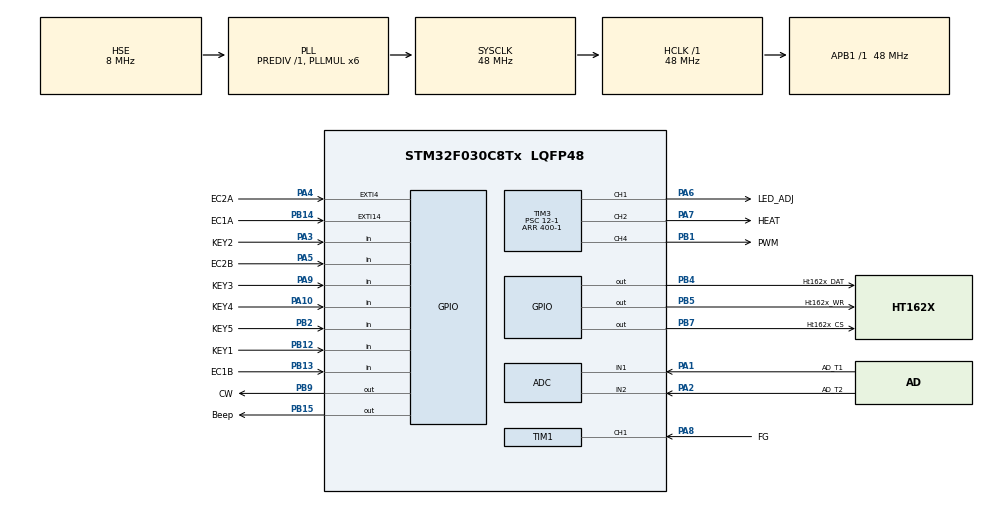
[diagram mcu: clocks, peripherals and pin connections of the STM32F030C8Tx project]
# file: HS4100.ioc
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ADC.DMAContinuousRequests=ENABLE
ADC.ExternalTrigConv=ADC_EXTERNALTRIGCONV_T15_TRGO
ADC.SamplingTime=ADC_SAMPLETIME_239CYCLES_5
Dma.ADC.0.Direction=DMA_PERIPH_TO_MEMORY
Dma.ADC.0.Instance=DMA1_Channel1
Dma.ADC.0.MemDataAlignment=DMA_MDATAALIGN_HALFWORD
Dma.ADC.0.MemInc=DMA_MINC_ENABLE
Dma.ADC.0.Mode=DMA_CIRCULAR
Dma.ADC.0.PeriphDataAlignment=DMA_PDATAALIGN_HALFWORD
Dma.ADC.0.PeriphInc=DMA_PINC_DISABLE
Dma.ADC.0.Priority=DMA_PRIORITY_HIGH
Dma.Request0=ADC
Mcu.Family=STM32F0
Mcu.Name=STM32F030C8Tx
Mcu.Package=LQFP48
NVIC.ADC1_IRQn=true\:0\:0\:false\:false\:true\:true\:true\:true
NVIC.DMA1_Channel1_IRQn=true\:0\:0\:false\:false\:true\:false\:true\:true
NVIC.EXTI4_15_IRQn=true\:1\:0\:true\:false\:true\:true\:true\:true
NVIC.TIM14_IRQn=true\:2\:0\:true\:false\:true\:true\:true\:true
NVIC.TIM15_IRQn=true\:0\:0\:false\:false\:true\:true\:true\:true
NVIC.TIM1_CC_IRQn=true\:0\:0\:false\:false\:true\:true\:true\:true
NVIC.TIM6_IRQn=true\:2\:0\:true\:false\:true\:true\:true\:true
PA1.GPIO_Label=AD_T1
PA1.Mode=IN1
PA1.Signal=ADC_IN1
PA10.GPIO_Label=KEY4
PA10.Signal=GPIO_Input
PA13.Mode=Serial_Wire
PA13.Signal=SYS_SWDIO
PA14.Mode=Serial_Wire
PA14.Signal=SYS_SWCLK
PA2.GPIO_Label=AD_T2
PA2.Mode=IN2
PA2.Signal=ADC_IN2
PA3.GPIO_Label=KEY2
PA3.Signal=GPIO_Input
PA4.GPIO_Label=EC2A
PA4.Signal=GPXTI4
PA5.GPIO_Label=EC2B
PA5.Signal=GPIO_Input
PA6.GPIO_Label=LED_ADJ
PA6.Signal=S_TIM3_CH1
PA7.GPIO_Label=HEAT
PA7.Signal=S_TIM3_CH2
PA8.GPIO_Label=FG
PA8.Signal=S_TIM1_CH1
PA9.GPIO_Label=KEY3
PA9.Signal=GPIO_Input
PB1.GPIO_Label=PWM
PB1.Signal=S_TIM3_CH4
PB12.GPIO_Label=KEY1
PB12.Signal=GPIO_Input
PB13.GPIO_Label=EC1B
PB13.Signal=GPIO_Input
PB14.GPIO_Label=EC1A
PB14.Signal=GPXTI14
PB15.GPIO_Label=Beep
PB15.Signal=GPIO_Output
PB2.GPIO_Label=KEY5
PB2.Signal=GPIO_Input
PB4.GPIO_Label=Ht162x_DAT
PB4.GPIO_ModeDefaultOutputPP=GPIO_MODE_OUTPUT_PP
PB4.GPIO_PuPd=GPIO_PULLUP
PB4.GPIO_Speed=GPIO_SPEED_FREQ_HIGH
PB4.PinState=GPIO_PIN_SET
PB4.Signal=GPIO_Output
PB5.GPIO_Label=Ht162x_WR
PB5.GPIO_PuPd=GPIO_PULLUP
PB5.GPIO_Speed=GPIO_SPEED_FREQ_HIGH
PB5.PinState=GPIO_PIN_SET
PB5.Signal=GPIO_Output
PB7.GPIO_Label=Ht162x_CS
PB7.GPIO_PuPd=GPIO_PULLUP
PB7.GPIO_Speed=GPIO_SPEED_FREQ_HIGH
PB7.PinState=GPIO_PIN_SET
PB7.Signal=GPIO_Output
PB9.GPIO_Label=CW
PB9.Signal=GPIO_Output
PF0-OSC_IN.Mode=HSE-External-Oscillator
PF0-OSC_IN.Signal=RCC_OSC_IN
PF1-OSC_OUT.Mode=HSE-External-Oscillator
PF1-OSC_OUT.Signal=RCC_OSC_OUT
ProjectManager.HeapSize=0x200
ProjectManager.StackSize=0x400
ProjectManager.TargetToolchain=MDK-ARM V5.32
RCC.AHBFreq_Value=48000000
RCC.APB1Freq_Value=48000000
RCC.APB1TimFreq_Value=48000000
RCC.HCLKFreq_Value=48000000
RCC.PLLMUL=RCC_PLL_MUL6
RCC.PLLSourceVirtual=RCC_PLLSOURCE_HSE
RCC.SYSCLKFreq_VALUE=48000000
RCC.SYSCLKSource=RCC_SYSCLKSOURCE_PLLCLK
SH.S_TIM1_CH1.0=TIM1_CH1,Input_Capture1_from_TI1
SH.S_TIM3_CH1.0=TIM3_CH1,PWM Generation1 CH1
SH.S_TIM3_CH2.0=TIM3_CH2,PWM Generation2 CH2
SH.S_TIM3_CH4.0=TIM3_CH4,PWM Generation4 CH4
TIM1.Channel-Input_Capture1_from_TI1=TIM_CHANNEL_1
TIM1.Prescaler=4800-1
TIM14.AutoReloadPreload=TIM_AUTORELOAD_PRELOAD_ENABLE
TIM14.Period=100-1
TIM14.Prescaler=480-1
TIM15.Period=1000-1
TIM15.Prescaler=48-1
TIM15.TIM_MasterOutputTrigger=TIM_TRGO_UPDATE
TIM3.Channel-PWM\ Generation1\ CH1=TIM_CHANNEL_1
TIM3.Channel-PWM\ Generation2\ CH2=TIM_CHANNEL_2
TIM3.Channel-PWM\ Generation4\ CH4=TIM_CHANNEL_4
TIM3.Period=400-1
TIM3.Prescaler=12-1
TIM6.AutoReloadPreload=TIM_AUTORELOAD_PRELOAD_ENABLE
TIM6.Period=100-1
TIM6.Prescaler=480-1
VP_ADC_Vref_Input.Mode=IN-Vrefint
VP_TIM14_VS_ClockSourceINT.Mode=Enable_Timer
VP_TIM15_VS_ClockSourceINT.Mode=Internal
VP_TIM6_VS_ClockSourceINT.Mode=Enable_Timer
board=custom

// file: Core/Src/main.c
/* USER CODE BEGIN Header */
/**
  ******************************************************************************
  * @file           : main.c
  * @brief          : Main program body
  ******************************************************************************
  * @attention
  *
  * <h2><center>&copy; Copyright (c) 2023 STMicroelectronics.
  * All rights reserved.</center></h2>
  *
  * This software component is licensed by ST under BSD 3-Clause license,
  * the "License"; You may not use this file except in compliance with the
  * License. You may obtain a copy of the License at:
  *                        opensource.org/licenses/BSD-3-Clause
  *
  ******************************************************************************
  */
/* USER CODE END Header */
#include "main.h"
#include "adc.h"
#include "dma.h"
#include "tim.h"
#include "gpio.h"

void SystemClock_Config(void);

int main(void)
{

  /* MCU Configuration--------------------------------------------------------*/

  /* Reset of all peripherals, Initializes the Flash interface and the Systick. */
  HAL_Init();

  /* Configure the system clock */
  SystemClock_Config();

  /* Initialize all configured peripherals */
  MX_GPIO_Init();
  MX_DMA_Init();
  MX_ADC_Init();
  MX_TIM1_Init();
  MX_TIM3_Init();
  MX_TIM6_Init();
  MX_TIM14_Init();
  MX_TIM15_Init();
  /* USER CODE BEGIN 2 */
	System_Init();//ϵͳ������ʼ��
  /* USER CODE END 2 */

  /* Infinite loop */
  while (1)
  {

    /* USER CODE BEGIN 3 */
      Show_Display();//��ʾ��Ļ����
  }
  /* USER CODE END 3 */
}

void SystemClock_Config(void)
{
  RCC_OscInitTypeDef RCC_OscInitStruct = {0};
  RCC_ClkInitTypeDef RCC_ClkInitStruct = {0};

  /** Initializes the RCC Oscillators according to the specified parameters
  * in the RCC_OscInitTypeDef structure.
  */
  RCC_OscInitStruct.OscillatorType = RCC_OSCILLATORTYPE_HSI14|RCC_OSCILLATORTYPE_HSE;
  RCC_OscInitStruct.HSEState = RCC_HSE_ON;
  RCC_OscInitStruct.HSI14State = RCC_HSI14_ON;
  RCC_OscInitStruct.HSI14CalibrationValue = 16;
  RCC_OscInitStruct.PLL.PLLState = RCC_PLL_ON;
  RCC_OscInitStruct.PLL.PLLSource = RCC_PLLSOURCE_HSE;
  RCC_OscInitStruct.PLL.PLLMUL = RCC_PLL_MUL6;
  RCC_OscInitStruct.PLL.PREDIV = RCC_PREDIV_DIV1;
  if (HAL_RCC_OscConfig(&RCC_OscInitStruct) != HAL_OK)
  {
    Error_Handler();
  }
  /** Initializes the CPU, AHB and APB buses clocks
  */
  RCC_ClkInitStruct.ClockType = RCC_CLOCKTYPE_HCLK|RCC_CLOCKTYPE_SYSCLK
                              |RCC_CLOCKTYPE_PCLK1;
  RCC_ClkInitStruct.SYSCLKSource = RCC_SYSCLKSOURCE_PLLCLK;
  RCC_ClkInitStruct.AHBCLKDivider = RCC_SYSCLK_DIV1;
  RCC_ClkInitStruct.APB1CLKDivider = RCC_HCLK_DIV1;

  if (HAL_RCC_ClockConfig(&RCC_ClkInitStruct, FLASH_LATENCY_1) != HAL_OK)
  {
    Error_Handler();
  }
}

void Error_Handler(void)
{
  __disable_irq();
  while (1)
  {
  }
}

/************************ (C) COPYRIGHT STMicroelectronics *****END OF FILE****/
